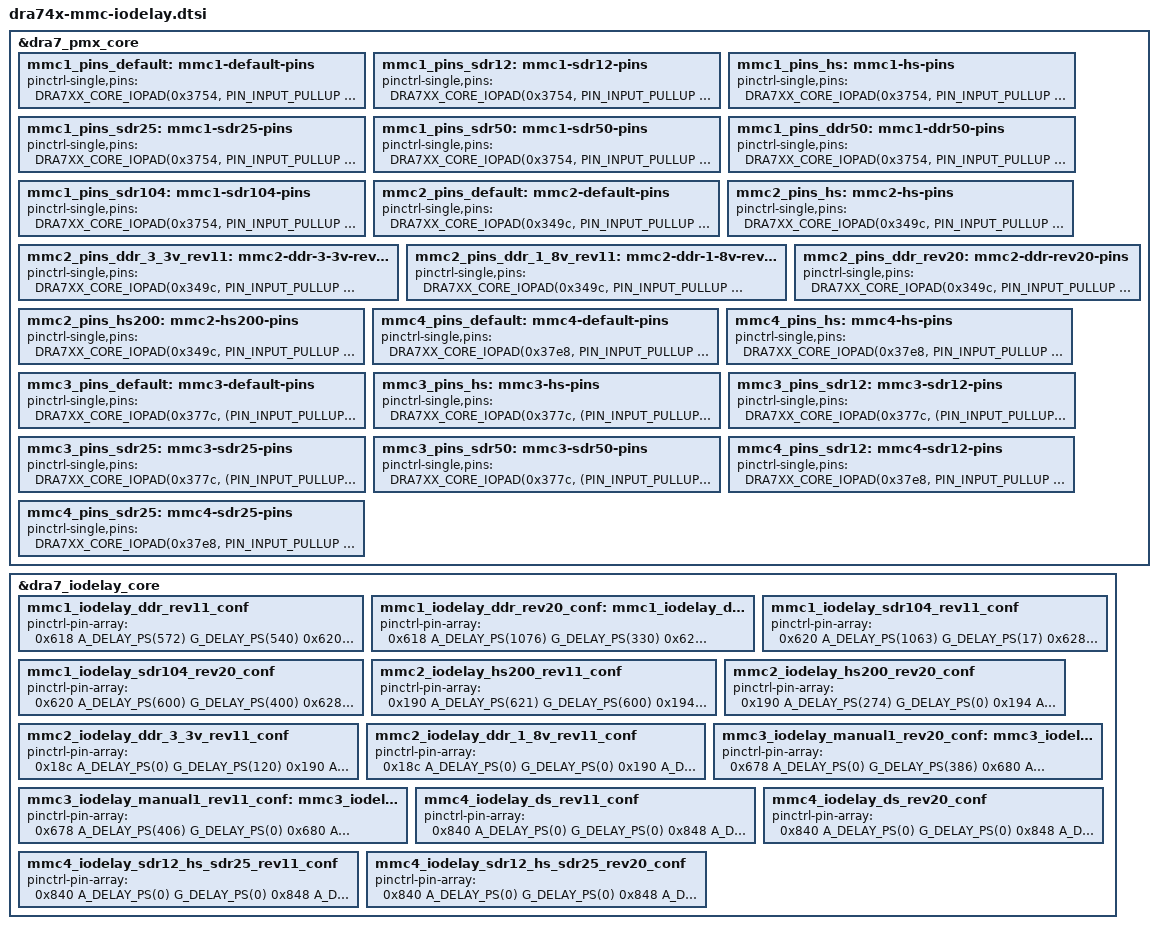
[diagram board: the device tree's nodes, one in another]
&dra7_pmx_core {
	mmc1_pins_default: mmc1-default-pins {
		pinctrl-single,pins = <
			DRA7XX_CORE_IOPAD(0x3754, PIN_INPUT_PULLUP | MUX_MODE0)  
			DRA7XX_CORE_IOPAD(0x3758, PIN_INPUT_PULLUP | MUX_MODE0)  
			DRA7XX_CORE_IOPAD(0x375c, PIN_INPUT_PULLUP | MUX_MODE0)  
			DRA7XX_CORE_IOPAD(0x3760, PIN_INPUT_PULLUP | MUX_MODE0)  
			DRA7XX_CORE_IOPAD(0x3764, PIN_INPUT_PULLUP | MUX_MODE0)  
			DRA7XX_CORE_IOPAD(0x3768, PIN_INPUT_PULLUP | MUX_MODE0)  
		>;
	};
	mmc1_pins_sdr12: mmc1-sdr12-pins {
		pinctrl-single,pins = <
			DRA7XX_CORE_IOPAD(0x3754, PIN_INPUT_PULLUP | MUX_MODE0)	 
			DRA7XX_CORE_IOPAD(0x3758, PIN_INPUT_PULLUP | MUX_MODE0)	 
			DRA7XX_CORE_IOPAD(0x375c, PIN_INPUT_PULLUP | MUX_MODE0)	 
			DRA7XX_CORE_IOPAD(0x3760, PIN_INPUT_PULLUP | MUX_MODE0)	 
			DRA7XX_CORE_IOPAD(0x3764, PIN_INPUT_PULLUP | MUX_MODE0)	 
			DRA7XX_CORE_IOPAD(0x3768, PIN_INPUT_PULLUP | MUX_MODE0)	 
		>;
	};
	mmc1_pins_hs: mmc1-hs-pins {
		pinctrl-single,pins = <
			DRA7XX_CORE_IOPAD(0x3754, PIN_INPUT_PULLUP | MUX_VIRTUAL_MODE11 | MUX_MODE0)  
			DRA7XX_CORE_IOPAD(0x3758, PIN_INPUT_PULLUP | MUX_VIRTUAL_MODE11 | MUX_MODE0)  
			DRA7XX_CORE_IOPAD(0x375c, PIN_INPUT_PULLUP | MUX_VIRTUAL_MODE11 | MUX_MODE0)  
			DRA7XX_CORE_IOPAD(0x3760, PIN_INPUT_PULLUP | MUX_VIRTUAL_MODE11 | MUX_MODE0)  
			DRA7XX_CORE_IOPAD(0x3764, PIN_INPUT_PULLUP | MUX_VIRTUAL_MODE11 | MUX_MODE0)  
			DRA7XX_CORE_IOPAD(0x3768, PIN_INPUT_PULLUP | MUX_VIRTUAL_MODE11 | MUX_MODE0)  
		>;
	};
	mmc1_pins_sdr25: mmc1-sdr25-pins {
		pinctrl-single,pins = <
			DRA7XX_CORE_IOPAD(0x3754, PIN_INPUT_PULLUP | MUX_VIRTUAL_MODE11 | MUX_MODE0)	 
			DRA7XX_CORE_IOPAD(0x3758, PIN_INPUT_PULLUP | MUX_VIRTUAL_MODE11 | MUX_MODE0)	 
			DRA7XX_CORE_IOPAD(0x375c, PIN_INPUT_PULLUP | MUX_VIRTUAL_MODE11 | MUX_MODE0)	 
			DRA7XX_CORE_IOPAD(0x3760, PIN_INPUT_PULLUP | MUX_VIRTUAL_MODE11 | MUX_MODE0)	 
			DRA7XX_CORE_IOPAD(0x3764, PIN_INPUT_PULLUP | MUX_VIRTUAL_MODE11 | MUX_MODE0)	 
			DRA7XX_CORE_IOPAD(0x3768, PIN_INPUT_PULLUP | MUX_VIRTUAL_MODE11 | MUX_MODE0)	 
		>;
	};
	mmc1_pins_sdr50: mmc1-sdr50-pins {
		pinctrl-single,pins = <
			DRA7XX_CORE_IOPAD(0x3754, PIN_INPUT_PULLUP | MUX_VIRTUAL_MODE10 | MUX_MODE0)	 
			DRA7XX_CORE_IOPAD(0x3758, PIN_INPUT_PULLUP | MUX_VIRTUAL_MODE10 | MUX_MODE0)	 
			DRA7XX_CORE_IOPAD(0x375c, PIN_INPUT_PULLUP | MUX_VIRTUAL_MODE10 | MUX_MODE0)	 
			DRA7XX_CORE_IOPAD(0x3760, PIN_INPUT_PULLUP | MUX_VIRTUAL_MODE10 | MUX_MODE0)	 
			DRA7XX_CORE_IOPAD(0x3764, PIN_INPUT_PULLUP | MUX_VIRTUAL_MODE10 | MUX_MODE0)	 
			DRA7XX_CORE_IOPAD(0x3768, PIN_INPUT_PULLUP | MUX_VIRTUAL_MODE10 | MUX_MODE0)	 
		>;
	};
	mmc1_pins_ddr50: mmc1-ddr50-pins {
		pinctrl-single,pins = <
			DRA7XX_CORE_IOPAD(0x3754, PIN_INPUT_PULLUP | MODE_SELECT | MUX_MODE0)	 
			DRA7XX_CORE_IOPAD(0x3758, PIN_INPUT_PULLUP | MODE_SELECT | MUX_MODE0)	 
			DRA7XX_CORE_IOPAD(0x375c, PIN_INPUT_PULLUP | MODE_SELECT | MUX_MODE0)	 
			DRA7XX_CORE_IOPAD(0x3760, PIN_INPUT_PULLUP | MODE_SELECT | MUX_MODE0)	 
			DRA7XX_CORE_IOPAD(0x3764, PIN_INPUT_PULLUP | MODE_SELECT | MUX_MODE0)	 
			DRA7XX_CORE_IOPAD(0x3768, PIN_INPUT_PULLUP | MODE_SELECT | MUX_MODE0)	 
		>;
	};
	mmc1_pins_sdr104: mmc1-sdr104-pins {
		pinctrl-single,pins = <
			DRA7XX_CORE_IOPAD(0x3754, PIN_INPUT_PULLUP | MODE_SELECT | MUX_MODE0)	 
			DRA7XX_CORE_IOPAD(0x3758, PIN_INPUT_PULLUP | MODE_SELECT | MUX_MODE0)	 
			DRA7XX_CORE_IOPAD(0x375c, PIN_INPUT_PULLUP | MODE_SELECT | MUX_MODE0)	 
			DRA7XX_CORE_IOPAD(0x3760, PIN_INPUT_PULLUP | MODE_SELECT | MUX_MODE0)	 
			DRA7XX_CORE_IOPAD(0x3764, PIN_INPUT_PULLUP | MODE_SELECT | MUX_MODE0)	 
			DRA7XX_CORE_IOPAD(0x3768, PIN_INPUT_PULLUP | MODE_SELECT | MUX_MODE0)	 
		>;
	};
	mmc2_pins_default: mmc2-default-pins {
		pinctrl-single,pins = <
			DRA7XX_CORE_IOPAD(0x349c, PIN_INPUT_PULLUP | MUX_MODE1)  
			DRA7XX_CORE_IOPAD(0x34b0, PIN_INPUT_PULLUP | MUX_MODE1)  
			DRA7XX_CORE_IOPAD(0x34a0, PIN_INPUT_PULLUP | MUX_MODE1)  
			DRA7XX_CORE_IOPAD(0x34a4, PIN_INPUT_PULLUP | MUX_MODE1)  
			DRA7XX_CORE_IOPAD(0x34a8, PIN_INPUT_PULLUP | MUX_MODE1)  
			DRA7XX_CORE_IOPAD(0x34ac, PIN_INPUT_PULLUP | MUX_MODE1)  
			DRA7XX_CORE_IOPAD(0x348c, PIN_INPUT_PULLUP | MUX_MODE1)  
			DRA7XX_CORE_IOPAD(0x3490, PIN_INPUT_PULLUP | MUX_MODE1)  
			DRA7XX_CORE_IOPAD(0x3494, PIN_INPUT_PULLUP | MUX_MODE1)  
			DRA7XX_CORE_IOPAD(0x3498, PIN_INPUT_PULLUP | MUX_MODE1)  
		>;
	};
	mmc2_pins_hs: mmc2-hs-pins {
		pinctrl-single,pins = <
			DRA7XX_CORE_IOPAD(0x349c, PIN_INPUT_PULLUP | MUX_MODE1)  
			DRA7XX_CORE_IOPAD(0x34b0, PIN_INPUT_PULLUP | MUX_MODE1)  
			DRA7XX_CORE_IOPAD(0x34a0, PIN_INPUT_PULLUP | MUX_MODE1)  
			DRA7XX_CORE_IOPAD(0x34a4, PIN_INPUT_PULLUP | MUX_MODE1)  
			DRA7XX_CORE_IOPAD(0x34a8, PIN_INPUT_PULLUP | MUX_MODE1)  
			DRA7XX_CORE_IOPAD(0x34ac, PIN_INPUT_PULLUP | MUX_MODE1)  
			DRA7XX_CORE_IOPAD(0x348c, PIN_INPUT_PULLUP | MUX_MODE1)  
			DRA7XX_CORE_IOPAD(0x3490, PIN_INPUT_PULLUP | MUX_MODE1)  
			DRA7XX_CORE_IOPAD(0x3494, PIN_INPUT_PULLUP | MUX_MODE1)  
			DRA7XX_CORE_IOPAD(0x3498, PIN_INPUT_PULLUP | MUX_MODE1)  
		>;
	};
	mmc2_pins_ddr_3_3v_rev11: mmc2-ddr-3-3v-rev11-pins {
		pinctrl-single,pins = <
			DRA7XX_CORE_IOPAD(0x349c, PIN_INPUT_PULLUP | MODE_SELECT | MUX_MODE1)  
			DRA7XX_CORE_IOPAD(0x34b0, PIN_INPUT_PULLUP | MODE_SELECT | MUX_MODE1)  
			DRA7XX_CORE_IOPAD(0x34a0, PIN_INPUT_PULLUP | MODE_SELECT | MUX_MODE1)  
			DRA7XX_CORE_IOPAD(0x34a4, PIN_INPUT_PULLUP | MODE_SELECT | MUX_MODE1)  
			DRA7XX_CORE_IOPAD(0x34a8, PIN_INPUT_PULLUP | MODE_SELECT | MUX_MODE1)  
			DRA7XX_CORE_IOPAD(0x34ac, PIN_INPUT_PULLUP | MODE_SELECT | MUX_MODE1)  
			DRA7XX_CORE_IOPAD(0x348c, PIN_INPUT_PULLUP | MODE_SELECT | MUX_MODE1)  
			DRA7XX_CORE_IOPAD(0x3490, PIN_INPUT_PULLUP | MODE_SELECT | MUX_MODE1)  
			DRA7XX_CORE_IOPAD(0x3494, PIN_INPUT_PULLUP | MODE_SELECT | MUX_MODE1)  
			DRA7XX_CORE_IOPAD(0x3498, PIN_INPUT_PULLUP | MODE_SELECT | MUX_MODE1)  
		>;
	};
	mmc2_pins_ddr_1_8v_rev11: mmc2-ddr-1-8v-rev11-pins {
		pinctrl-single,pins = <
			DRA7XX_CORE_IOPAD(0x349c, PIN_INPUT_PULLUP | MODE_SELECT | MUX_MODE1)  
			DRA7XX_CORE_IOPAD(0x34b0, PIN_INPUT_PULLUP | MODE_SELECT | MUX_MODE1)  
			DRA7XX_CORE_IOPAD(0x34a0, PIN_INPUT_PULLUP | MODE_SELECT | MUX_MODE1)  
			DRA7XX_CORE_IOPAD(0x34a4, PIN_INPUT_PULLUP | MODE_SELECT | MUX_MODE1)  
			DRA7XX_CORE_IOPAD(0x34a8, PIN_INPUT_PULLUP | MODE_SELECT | MUX_MODE1)  
			DRA7XX_CORE_IOPAD(0x34ac, PIN_INPUT_PULLUP | MODE_SELECT | MUX_MODE1)  
			DRA7XX_CORE_IOPAD(0x348c, PIN_INPUT_PULLUP | MODE_SELECT | MUX_MODE1)  
			DRA7XX_CORE_IOPAD(0x3490, PIN_INPUT_PULLUP | MODE_SELECT | MUX_MODE1)  
			DRA7XX_CORE_IOPAD(0x3494, PIN_INPUT_PULLUP | MODE_SELECT | MUX_MODE1)  
			DRA7XX_CORE_IOPAD(0x3498, PIN_INPUT_PULLUP | MODE_SELECT | MUX_MODE1)  
		>;
	};
	mmc2_pins_ddr_rev20: mmc2-ddr-rev20-pins {
		pinctrl-single,pins = <
			DRA7XX_CORE_IOPAD(0x349c, PIN_INPUT_PULLUP | MUX_MODE1)  
			DRA7XX_CORE_IOPAD(0x34b0, PIN_INPUT_PULLUP | MUX_MODE1)  
			DRA7XX_CORE_IOPAD(0x34a0, PIN_INPUT_PULLUP | MUX_MODE1)  
			DRA7XX_CORE_IOPAD(0x34a4, PIN_INPUT_PULLUP | MUX_MODE1)  
			DRA7XX_CORE_IOPAD(0x34a8, PIN_INPUT_PULLUP | MUX_MODE1)  
			DRA7XX_CORE_IOPAD(0x34ac, PIN_INPUT_PULLUP | MUX_MODE1)  
			DRA7XX_CORE_IOPAD(0x348c, PIN_INPUT_PULLUP | MUX_MODE1)  
			DRA7XX_CORE_IOPAD(0x3490, PIN_INPUT_PULLUP | MUX_MODE1)  
			DRA7XX_CORE_IOPAD(0x3494, PIN_INPUT_PULLUP | MUX_MODE1)  
			DRA7XX_CORE_IOPAD(0x3498, PIN_INPUT_PULLUP | MUX_MODE1)  
		>;
	};
	mmc2_pins_hs200: mmc2-hs200-pins {
		pinctrl-single,pins = <
			DRA7XX_CORE_IOPAD(0x349c, PIN_INPUT_PULLUP | MODE_SELECT | MUX_MODE1)  
			DRA7XX_CORE_IOPAD(0x34b0, PIN_INPUT_PULLUP | MODE_SELECT | MUX_MODE1)  
			DRA7XX_CORE_IOPAD(0x34a0, PIN_INPUT_PULLUP | MODE_SELECT | MUX_MODE1)  
			DRA7XX_CORE_IOPAD(0x34a4, PIN_INPUT_PULLUP | MODE_SELECT | MUX_MODE1)  
			DRA7XX_CORE_IOPAD(0x34a8, PIN_INPUT_PULLUP | MODE_SELECT | MUX_MODE1)  
			DRA7XX_CORE_IOPAD(0x34ac, PIN_INPUT_PULLUP | MODE_SELECT | MUX_MODE1)  
			DRA7XX_CORE_IOPAD(0x348c, PIN_INPUT_PULLUP | MODE_SELECT | MUX_MODE1)  
			DRA7XX_CORE_IOPAD(0x3490, PIN_INPUT_PULLUP | MODE_SELECT | MUX_MODE1)  
			DRA7XX_CORE_IOPAD(0x3494, PIN_INPUT_PULLUP | MODE_SELECT | MUX_MODE1)  
			DRA7XX_CORE_IOPAD(0x3498, PIN_INPUT_PULLUP | MODE_SELECT | MUX_MODE1)  
		>;
	};
	mmc4_pins_default: mmc4-default-pins {
		pinctrl-single,pins = <
			DRA7XX_CORE_IOPAD(0x37e8, PIN_INPUT_PULLUP | MODE_SELECT | MUX_MODE3)  
			DRA7XX_CORE_IOPAD(0x37ec, PIN_INPUT_PULLUP | MODE_SELECT | MUX_MODE3)  
			DRA7XX_CORE_IOPAD(0x37f0, PIN_INPUT_PULLUP | MODE_SELECT | MUX_MODE3)  
			DRA7XX_CORE_IOPAD(0x37f4, PIN_INPUT_PULLUP | MODE_SELECT | MUX_MODE3)  
			DRA7XX_CORE_IOPAD(0x37f8, PIN_INPUT_PULLUP | MODE_SELECT | MUX_MODE3)  
			DRA7XX_CORE_IOPAD(0x37fc, PIN_INPUT_PULLUP | MODE_SELECT | MUX_MODE3)  
		>;
	};
	mmc4_pins_hs: mmc4-hs-pins {
		pinctrl-single,pins = <
			DRA7XX_CORE_IOPAD(0x37e8, PIN_INPUT_PULLUP | MODE_SELECT | MUX_MODE3)  
			DRA7XX_CORE_IOPAD(0x37ec, PIN_INPUT_PULLUP | MODE_SELECT | MUX_MODE3)  
			DRA7XX_CORE_IOPAD(0x37f0, PIN_INPUT_PULLUP | MODE_SELECT | MUX_MODE3)  
			DRA7XX_CORE_IOPAD(0x37f4, PIN_INPUT_PULLUP | MODE_SELECT | MUX_MODE3)  
			DRA7XX_CORE_IOPAD(0x37f8, PIN_INPUT_PULLUP | MODE_SELECT | MUX_MODE3)  
			DRA7XX_CORE_IOPAD(0x37fc, PIN_INPUT_PULLUP | MODE_SELECT | MUX_MODE3)  
		>;
	};
	mmc3_pins_default: mmc3-default-pins {
		pinctrl-single,pins = <
			DRA7XX_CORE_IOPAD(0x377c, (PIN_INPUT_PULLUP | MODE_SELECT | MUX_MODE0))  
			DRA7XX_CORE_IOPAD(0x3780, (PIN_INPUT_PULLUP | MODE_SELECT | MUX_MODE0))  
			DRA7XX_CORE_IOPAD(0x3784, (PIN_INPUT_PULLUP | MODE_SELECT | MUX_MODE0))  
			DRA7XX_CORE_IOPAD(0x3788, (PIN_INPUT_PULLUP | MODE_SELECT | MUX_MODE0))  
			DRA7XX_CORE_IOPAD(0x378c, (PIN_INPUT_PULLUP | MODE_SELECT | MUX_MODE0))  
			DRA7XX_CORE_IOPAD(0x3790, (PIN_INPUT_PULLUP | MODE_SELECT | MUX_MODE0))  
		>;
	};
	mmc3_pins_hs: mmc3-hs-pins {
		pinctrl-single,pins = <
			DRA7XX_CORE_IOPAD(0x377c, (PIN_INPUT_PULLUP | MODE_SELECT | MUX_MODE0))  
			DRA7XX_CORE_IOPAD(0x3780, (PIN_INPUT_PULLUP | MODE_SELECT | MUX_MODE0))  
			DRA7XX_CORE_IOPAD(0x3784, (PIN_INPUT_PULLUP | MODE_SELECT | MUX_MODE0))  
			DRA7XX_CORE_IOPAD(0x3788, (PIN_INPUT_PULLUP | MODE_SELECT | MUX_MODE0))  
			DRA7XX_CORE_IOPAD(0x378c, (PIN_INPUT_PULLUP | MODE_SELECT | MUX_MODE0))  
			DRA7XX_CORE_IOPAD(0x3790, (PIN_INPUT_PULLUP | MODE_SELECT | MUX_MODE0))  
		>;
	};
	mmc3_pins_sdr12: mmc3-sdr12-pins {
		pinctrl-single,pins = <
			DRA7XX_CORE_IOPAD(0x377c, (PIN_INPUT_PULLUP | MODE_SELECT | MUX_MODE0))  
			DRA7XX_CORE_IOPAD(0x3780, (PIN_INPUT_PULLUP | MODE_SELECT | MUX_MODE0))  
			DRA7XX_CORE_IOPAD(0x3784, (PIN_INPUT_PULLUP | MODE_SELECT | MUX_MODE0))  
			DRA7XX_CORE_IOPAD(0x3788, (PIN_INPUT_PULLUP | MODE_SELECT | MUX_MODE0))  
			DRA7XX_CORE_IOPAD(0x378c, (PIN_INPUT_PULLUP | MODE_SELECT | MUX_MODE0))  
			DRA7XX_CORE_IOPAD(0x3790, (PIN_INPUT_PULLUP | MODE_SELECT | MUX_MODE0))  
		>;
	};
	mmc3_pins_sdr25: mmc3-sdr25-pins {
		pinctrl-single,pins = <
			DRA7XX_CORE_IOPAD(0x377c, (PIN_INPUT_PULLUP | MODE_SELECT | MUX_MODE0))  
			DRA7XX_CORE_IOPAD(0x3780, (PIN_INPUT_PULLUP | MODE_SELECT | MUX_MODE0))  
			DRA7XX_CORE_IOPAD(0x3784, (PIN_INPUT_PULLUP | MODE_SELECT | MUX_MODE0))  
			DRA7XX_CORE_IOPAD(0x3788, (PIN_INPUT_PULLUP | MODE_SELECT | MUX_MODE0))  
			DRA7XX_CORE_IOPAD(0x378c, (PIN_INPUT_PULLUP | MODE_SELECT | MUX_MODE0))  
			DRA7XX_CORE_IOPAD(0x3790, (PIN_INPUT_PULLUP | MODE_SELECT | MUX_MODE0))  
		>;
	};
	mmc3_pins_sdr50: mmc3-sdr50-pins {
		pinctrl-single,pins = <
			DRA7XX_CORE_IOPAD(0x377c, (PIN_INPUT_PULLUP | MODE_SELECT | MUX_MODE0))  
			DRA7XX_CORE_IOPAD(0x3780, (PIN_INPUT_PULLUP | MODE_SELECT | MUX_MODE0))  
			DRA7XX_CORE_IOPAD(0x3784, (PIN_INPUT_PULLUP | MODE_SELECT | MUX_MODE0))  
			DRA7XX_CORE_IOPAD(0x3788, (PIN_INPUT_PULLUP | MODE_SELECT | MUX_MODE0))  
			DRA7XX_CORE_IOPAD(0x378c, (PIN_INPUT_PULLUP | MODE_SELECT | MUX_MODE0))  
			DRA7XX_CORE_IOPAD(0x3790, (PIN_INPUT_PULLUP | MODE_SELECT | MUX_MODE0))  
		>;
	};
	mmc4_pins_sdr12: mmc4-sdr12-pins {
		pinctrl-single,pins = <
			DRA7XX_CORE_IOPAD(0x37e8, PIN_INPUT_PULLUP | MODE_SELECT | MUX_MODE3)  
			DRA7XX_CORE_IOPAD(0x37ec, PIN_INPUT_PULLUP | MODE_SELECT | MUX_MODE3)  
			DRA7XX_CORE_IOPAD(0x37f0, PIN_INPUT_PULLUP | MODE_SELECT | MUX_MODE3)  
			DRA7XX_CORE_IOPAD(0x37f4, PIN_INPUT_PULLUP | MODE_SELECT | MUX_MODE3)  
			DRA7XX_CORE_IOPAD(0x37f8, PIN_INPUT_PULLUP | MODE_SELECT | MUX_MODE3)  
			DRA7XX_CORE_IOPAD(0x37fc, PIN_INPUT_PULLUP | MODE_SELECT | MUX_MODE3)  
		>;
	};
	mmc4_pins_sdr25: mmc4-sdr25-pins {
		pinctrl-single,pins = <
			DRA7XX_CORE_IOPAD(0x37e8, PIN_INPUT_PULLUP | MODE_SELECT | MUX_MODE3)  
			DRA7XX_CORE_IOPAD(0x37ec, PIN_INPUT_PULLUP | MODE_SELECT | MUX_MODE3)  
			DRA7XX_CORE_IOPAD(0x37f0, PIN_INPUT_PULLUP | MODE_SELECT | MUX_MODE3)  
			DRA7XX_CORE_IOPAD(0x37f4, PIN_INPUT_PULLUP | MODE_SELECT | MUX_MODE3)  
			DRA7XX_CORE_IOPAD(0x37f8, PIN_INPUT_PULLUP | MODE_SELECT | MUX_MODE3)  
			DRA7XX_CORE_IOPAD(0x37fc, PIN_INPUT_PULLUP | MODE_SELECT | MUX_MODE3)  
		>;
	};
};
&dra7_iodelay_core {
	mmc1_iodelay_ddr_rev11_conf: mmc1_iodelay_ddr_rev11_conf {
		pinctrl-pin-array = <
			0x618 A_DELAY_PS(572) G_DELAY_PS(540)	 
			0x620 A_DELAY_PS(1525) G_DELAY_PS(0)	 
			0x624 A_DELAY_PS(0) G_DELAY_PS(600)	 
			0x628 A_DELAY_PS(0) G_DELAY_PS(0)	 
			0x62c A_DELAY_PS(55) G_DELAY_PS(0)	 
			0x630 A_DELAY_PS(403) G_DELAY_PS(120)	 
			0x634 A_DELAY_PS(0) G_DELAY_PS(0)	 
			0x638 A_DELAY_PS(0) G_DELAY_PS(0)	 
			0x63c A_DELAY_PS(23) G_DELAY_PS(60)	 
			0x640 A_DELAY_PS(0) G_DELAY_PS(0)	 
			0x644 A_DELAY_PS(0) G_DELAY_PS(0)	 
			0x648 A_DELAY_PS(25) G_DELAY_PS(60)	 
			0x64c A_DELAY_PS(0) G_DELAY_PS(0)	 
			0x650 A_DELAY_PS(0) G_DELAY_PS(0)	 
			0x654 A_DELAY_PS(0) G_DELAY_PS(0)	 
			0x658 A_DELAY_PS(0) G_DELAY_PS(0)	 
			0x65c A_DELAY_PS(0) G_DELAY_PS(0)	 
		>;
	};
	mmc1_iodelay_ddr_rev20_conf: mmc1_iodelay_ddr50_rev20_conf {
		pinctrl-pin-array = <
			0x618 A_DELAY_PS(1076) G_DELAY_PS(330)	 
			0x620 A_DELAY_PS(1271) G_DELAY_PS(0)	 
			0x624 A_DELAY_PS(722) G_DELAY_PS(0)	 
			0x628 A_DELAY_PS(0) G_DELAY_PS(0)	 
			0x62C A_DELAY_PS(0) G_DELAY_PS(0)	 
			0x630 A_DELAY_PS(751) G_DELAY_PS(0)	 
			0x634 A_DELAY_PS(0) G_DELAY_PS(0)	 
			0x638 A_DELAY_PS(20) G_DELAY_PS(0)	 
			0x63C A_DELAY_PS(256) G_DELAY_PS(0)	 
			0x640 A_DELAY_PS(0) G_DELAY_PS(0)	 
			0x644 A_DELAY_PS(0) G_DELAY_PS(0)	 
			0x648 A_DELAY_PS(263) G_DELAY_PS(0)	 
			0x64C A_DELAY_PS(0) G_DELAY_PS(0)	 
			0x650 A_DELAY_PS(0) G_DELAY_PS(0)	 
			0x654 A_DELAY_PS(0) G_DELAY_PS(0)	 
			0x658 A_DELAY_PS(0) G_DELAY_PS(0)	 
			0x65C A_DELAY_PS(0) G_DELAY_PS(0)	 
		>;
	};
	mmc1_iodelay_sdr104_rev11_conf: mmc1_iodelay_sdr104_rev11_conf {
		pinctrl-pin-array = <
			0x620 A_DELAY_PS(1063) G_DELAY_PS(17)	 
			0x628 A_DELAY_PS(0) G_DELAY_PS(0)	 
			0x62c A_DELAY_PS(23) G_DELAY_PS(0)	 
			0x634 A_DELAY_PS(0) G_DELAY_PS(0)	 
			0x638 A_DELAY_PS(0) G_DELAY_PS(0)	 
			0x640 A_DELAY_PS(0) G_DELAY_PS(0)	 
			0x644 A_DELAY_PS(2) G_DELAY_PS(0)	 
			0x64c A_DELAY_PS(0) G_DELAY_PS(0)	 
			0x650 A_DELAY_PS(0) G_DELAY_PS(0)	 
			0x658 A_DELAY_PS(0) G_DELAY_PS(0)	 
			0x65c A_DELAY_PS(0) G_DELAY_PS(0)	 
		>;
	};
	mmc1_iodelay_sdr104_rev20_conf: mmc1_iodelay_sdr104_rev20_conf {
		pinctrl-pin-array = <
			0x620 A_DELAY_PS(600) G_DELAY_PS(400)	 
			0x628 A_DELAY_PS(0) G_DELAY_PS(0)	 
			0x62c A_DELAY_PS(0) G_DELAY_PS(0)	 
			0x634 A_DELAY_PS(0) G_DELAY_PS(0)	 
			0x638 A_DELAY_PS(30) G_DELAY_PS(0)	 
			0x640 A_DELAY_PS(0) G_DELAY_PS(0)	 
			0x644 A_DELAY_PS(0) G_DELAY_PS(0)	 
			0x64c A_DELAY_PS(0) G_DELAY_PS(0)	 
			0x650 A_DELAY_PS(0) G_DELAY_PS(0)	 
			0x658 A_DELAY_PS(0) G_DELAY_PS(0)	 
			0x65c A_DELAY_PS(0) G_DELAY_PS(0)	 
		>;
	};
	mmc2_iodelay_hs200_rev11_conf: mmc2_iodelay_hs200_rev11_conf {
		pinctrl-pin-array = <
			0x190 A_DELAY_PS(621) G_DELAY_PS(600)	 
			0x194 A_DELAY_PS(300) G_DELAY_PS(0)	 
			0x1a8 A_DELAY_PS(739) G_DELAY_PS(600)	 
			0x1ac A_DELAY_PS(240) G_DELAY_PS(0)	 
			0x1b4 A_DELAY_PS(812) G_DELAY_PS(600)	 
			0x1b8 A_DELAY_PS(240) G_DELAY_PS(0)	 
			0x1c0 A_DELAY_PS(954) G_DELAY_PS(600)	 
			0x1c4 A_DELAY_PS(60)  G_DELAY_PS(0)	 
			0x1d0 A_DELAY_PS(1340) G_DELAY_PS(420)	 
			0x1d8 A_DELAY_PS(935) G_DELAY_PS(600)	 
			0x1dc A_DELAY_PS(0) G_DELAY_PS(0)	 
			0x1e4 A_DELAY_PS(525) G_DELAY_PS(600)	 
			0x1e8 A_DELAY_PS(120) G_DELAY_PS(0)	 
			0x1f0 A_DELAY_PS(767) G_DELAY_PS(600)	 
			0x1f4 A_DELAY_PS(225) G_DELAY_PS(0)	 
			0x1fc A_DELAY_PS(565) G_DELAY_PS(600)	 
			0x200 A_DELAY_PS(60) G_DELAY_PS(0)	 
			0x364 A_DELAY_PS(969) G_DELAY_PS(600)	 
			0x368 A_DELAY_PS(180) G_DELAY_PS(0)	 
	      >;
	};
	mmc2_iodelay_hs200_rev20_conf: mmc2_iodelay_hs200_rev20_conf {
		pinctrl-pin-array = <
			0x190 A_DELAY_PS(274) G_DELAY_PS(0)        
			0x194 A_DELAY_PS(162) G_DELAY_PS(0)        
			0x1a8 A_DELAY_PS(401) G_DELAY_PS(0)        
			0x1ac A_DELAY_PS(73) G_DELAY_PS(0)         
			0x1b4 A_DELAY_PS(465) G_DELAY_PS(0)        
			0x1b8 A_DELAY_PS(115) G_DELAY_PS(0)        
			0x1c0 A_DELAY_PS(633) G_DELAY_PS(0)        
			0x1c4 A_DELAY_PS(47) G_DELAY_PS(0)         
			0x1d0 A_DELAY_PS(935) G_DELAY_PS(280)      
			0x1d8 A_DELAY_PS(621) G_DELAY_PS(0)        
			0x1dc A_DELAY_PS(0) G_DELAY_PS(0)          
			0x1e4 A_DELAY_PS(183) G_DELAY_PS(0)        
			0x1e8 A_DELAY_PS(0) G_DELAY_PS(0)          
			0x1f0 A_DELAY_PS(467) G_DELAY_PS(0)        
			0x1f4 A_DELAY_PS(0) G_DELAY_PS(0)          
			0x1fc A_DELAY_PS(262) G_DELAY_PS(0)        
			0x200 A_DELAY_PS(46) G_DELAY_PS(0)         
			0x364 A_DELAY_PS(684) G_DELAY_PS(0)        
			0x368 A_DELAY_PS(76) G_DELAY_PS(0)         
	      >;
	};
	mmc2_iodelay_ddr_3_3v_rev11_conf: mmc2_iodelay_ddr_3_3v_rev11_conf {
		pinctrl-pin-array = <
			0x18c A_DELAY_PS(0) G_DELAY_PS(120)	 
			0x190 A_DELAY_PS(0) G_DELAY_PS(0)	 
			0x194 A_DELAY_PS(174) G_DELAY_PS(0)	 
			0x1a4 A_DELAY_PS(265) G_DELAY_PS(360)	 
			0x1a8 A_DELAY_PS(0) G_DELAY_PS(0)	 
			0x1ac A_DELAY_PS(168) G_DELAY_PS(0)	 
			0x1b0 A_DELAY_PS(0) G_DELAY_PS(120)	 
			0x1b4 A_DELAY_PS(0) G_DELAY_PS(0)	 
			0x1b8 A_DELAY_PS(136) G_DELAY_PS(0)	 
			0x1bc A_DELAY_PS(0) G_DELAY_PS(120)	 
			0x1c0 A_DELAY_PS(0) G_DELAY_PS(0)	 
			0x1c4 A_DELAY_PS(0) G_DELAY_PS(0)	 
			0x1c8 A_DELAY_PS(287) G_DELAY_PS(420)	 
			0x1d0 A_DELAY_PS(879) G_DELAY_PS(0)	 
			0x1d4 A_DELAY_PS(144) G_DELAY_PS(240)	 
			0x1d8 A_DELAY_PS(0) G_DELAY_PS(0)	 
			0x1dc A_DELAY_PS(0) G_DELAY_PS(0)	 
			0x1e0 A_DELAY_PS(0) G_DELAY_PS(0)	 
			0x1e4 A_DELAY_PS(0) G_DELAY_PS(0)	 
			0x1e8 A_DELAY_PS(34) G_DELAY_PS(0)	 
			0x1ec A_DELAY_PS(0) G_DELAY_PS(120)	 
			0x1f0 A_DELAY_PS(0) G_DELAY_PS(0)	 
			0x1f4 A_DELAY_PS(120) G_DELAY_PS(0)	 
			0x1f8 A_DELAY_PS(120) G_DELAY_PS(180)	 
			0x1fc A_DELAY_PS(0) G_DELAY_PS(0)	 
			0x200 A_DELAY_PS(0) G_DELAY_PS(0)	 
			0x360 A_DELAY_PS(0) G_DELAY_PS(0)	 
			0x364 A_DELAY_PS(0) G_DELAY_PS(0)	 
			0x368 A_DELAY_PS(11) G_DELAY_PS(0)	 
		>;
	};
	mmc2_iodelay_ddr_1_8v_rev11_conf: mmc2_iodelay_ddr_1_8v_rev11_conf {
		pinctrl-pin-array = <
			0x18c A_DELAY_PS(0) G_DELAY_PS(0)	 
			0x190 A_DELAY_PS(0) G_DELAY_PS(0)	 
			0x194 A_DELAY_PS(174) G_DELAY_PS(0)	 
			0x1a4 A_DELAY_PS(274) G_DELAY_PS(240)	 
			0x1a8 A_DELAY_PS(0) G_DELAY_PS(0)	 
			0x1ac A_DELAY_PS(168) G_DELAY_PS(0)	 
			0x1b0 A_DELAY_PS(0) G_DELAY_PS(60)	 
			0x1b4 A_DELAY_PS(0) G_DELAY_PS(0)	 
			0x1b8 A_DELAY_PS(136) G_DELAY_PS(0)	 
			0x1bc A_DELAY_PS(0) G_DELAY_PS(60)	 
			0x1c0 A_DELAY_PS(0) G_DELAY_PS(0)	 
			0x1c4 A_DELAY_PS(0) G_DELAY_PS(0)	 
			0x1c8 A_DELAY_PS(514) G_DELAY_PS(360)	 
			0x1d0 A_DELAY_PS(879) G_DELAY_PS(0)	 
			0x1d4 A_DELAY_PS(187) G_DELAY_PS(120)	 
			0x1d8 A_DELAY_PS(0) G_DELAY_PS(0)	 
			0x1dc A_DELAY_PS(0) G_DELAY_PS(0)	 
			0x1e0 A_DELAY_PS(0) G_DELAY_PS(0)	 
			0x1e4 A_DELAY_PS(0) G_DELAY_PS(0)	 
			0x1e8 A_DELAY_PS(34) G_DELAY_PS(0)	 
			0x1ec A_DELAY_PS(0) G_DELAY_PS(60)	 
			0x1f0 A_DELAY_PS(0) G_DELAY_PS(0)	 
			0x1f4 A_DELAY_PS(120) G_DELAY_PS(0)	 
			0x1f8 A_DELAY_PS(121) G_DELAY_PS(60)	 
			0x1fc A_DELAY_PS(0) G_DELAY_PS(0)	 
			0x200 A_DELAY_PS(0) G_DELAY_PS(0)	 
			0x360 A_DELAY_PS(0) G_DELAY_PS(0)	 
			0x364 A_DELAY_PS(0) G_DELAY_PS(0)	 
			0x368 A_DELAY_PS(11) G_DELAY_PS(0)	 
		>;
	};
	mmc3_iodelay_manual1_rev20_conf: mmc3_iodelay_manual1_conf {
		pinctrl-pin-array = <
			0x678 A_DELAY_PS(0) G_DELAY_PS(386)	 
			0x680 A_DELAY_PS(605) G_DELAY_PS(0)	 
			0x684 A_DELAY_PS(0) G_DELAY_PS(0)	 
			0x688 A_DELAY_PS(0) G_DELAY_PS(0)	 
			0x68c A_DELAY_PS(0) G_DELAY_PS(0)	 
			0x690 A_DELAY_PS(171) G_DELAY_PS(0)	 
			0x694 A_DELAY_PS(0) G_DELAY_PS(0)	 
			0x698 A_DELAY_PS(0) G_DELAY_PS(0)	 
			0x69c A_DELAY_PS(221) G_DELAY_PS(0)	 
			0x6a0 A_DELAY_PS(0) G_DELAY_PS(0)	 
			0x6a4 A_DELAY_PS(0) G_DELAY_PS(0)	 
			0x6a8 A_DELAY_PS(0) G_DELAY_PS(0)	 
			0x6ac A_DELAY_PS(0) G_DELAY_PS(0)	 
			0x6b0 A_DELAY_PS(0) G_DELAY_PS(0)	 
			0x6b4 A_DELAY_PS(474) G_DELAY_PS(0)	 
			0x6b8 A_DELAY_PS(0) G_DELAY_PS(0)	 
			0x6bc A_DELAY_PS(0) G_DELAY_PS(0)	 
		>;
	};
	mmc3_iodelay_manual1_rev11_conf: mmc3_iodelay_manual1_conf {
		pinctrl-pin-array = <
			0x678 A_DELAY_PS(406) G_DELAY_PS(0)	 
			0x680 A_DELAY_PS(659) G_DELAY_PS(0)	 
			0x684 A_DELAY_PS(0) G_DELAY_PS(0)	 
			0x688 A_DELAY_PS(0) G_DELAY_PS(0)	 
			0x68c A_DELAY_PS(0) G_DELAY_PS(0)	 
			0x690 A_DELAY_PS(130) G_DELAY_PS(0)	 
			0x694 A_DELAY_PS(0) G_DELAY_PS(0)	 
			0x698 A_DELAY_PS(0) G_DELAY_PS(0)	 
			0x69c A_DELAY_PS(169) G_DELAY_PS(0)	 
			0x6a0 A_DELAY_PS(0) G_DELAY_PS(0)	 
			0x6a4 A_DELAY_PS(0) G_DELAY_PS(0)	 
			0x6a8 A_DELAY_PS(0) G_DELAY_PS(0)	 
			0x6ac A_DELAY_PS(0) G_DELAY_PS(0)	 
			0x6b0 A_DELAY_PS(0) G_DELAY_PS(0)	 
			0x6b4 A_DELAY_PS(457) G_DELAY_PS(0)	 
			0x6b8 A_DELAY_PS(0) G_DELAY_PS(0)	 
			0x6bc A_DELAY_PS(0) G_DELAY_PS(0)	 
		>;
	};
	mmc4_iodelay_ds_rev11_conf: mmc4_iodelay_ds_rev11_conf {
		pinctrl-pin-array = <
			0x840 A_DELAY_PS(0) G_DELAY_PS(0)	 
			0x848 A_DELAY_PS(0) G_DELAY_PS(0)	 
			0x84c A_DELAY_PS(96) G_DELAY_PS(0)	 
			0x850 A_DELAY_PS(0) G_DELAY_PS(0)	 
			0x854 A_DELAY_PS(0) G_DELAY_PS(0)	 
			0x870 A_DELAY_PS(582) G_DELAY_PS(0)	 
			0x874 A_DELAY_PS(0) G_DELAY_PS(0)	 
			0x878 A_DELAY_PS(0) G_DELAY_PS(0)	 
			0x87c A_DELAY_PS(391) G_DELAY_PS(0)	 
			0x880 A_DELAY_PS(0) G_DELAY_PS(0)	 
			0x884 A_DELAY_PS(0) G_DELAY_PS(0)	 
			0x888 A_DELAY_PS(561) G_DELAY_PS(0)	 
			0x88c A_DELAY_PS(0) G_DELAY_PS(0)	 
			0x890 A_DELAY_PS(0) G_DELAY_PS(0)	 
			0x894 A_DELAY_PS(588) G_DELAY_PS(0)	 
			0x898 A_DELAY_PS(0) G_DELAY_PS(0)	 
			0x89c A_DELAY_PS(0) G_DELAY_PS(0)	 
		>;
	};
	mmc4_iodelay_ds_rev20_conf: mmc4_iodelay_ds_rev20_conf {
		pinctrl-pin-array = <
			0x840 A_DELAY_PS(0) G_DELAY_PS(0)	 
			0x848 A_DELAY_PS(0) G_DELAY_PS(0)	 
			0x84c A_DELAY_PS(307) G_DELAY_PS(0)	 
			0x850 A_DELAY_PS(0) G_DELAY_PS(0)	 
			0x854 A_DELAY_PS(0) G_DELAY_PS(0)	 
			0x870 A_DELAY_PS(785) G_DELAY_PS(0)	 
			0x874 A_DELAY_PS(0) G_DELAY_PS(0)	 
			0x878 A_DELAY_PS(0) G_DELAY_PS(0)	 
			0x87c A_DELAY_PS(613) G_DELAY_PS(0)	 
			0x880 A_DELAY_PS(0) G_DELAY_PS(0)	 
			0x884 A_DELAY_PS(0) G_DELAY_PS(0)	 
			0x888 A_DELAY_PS(683) G_DELAY_PS(0)	 
			0x88c A_DELAY_PS(0) G_DELAY_PS(0)	 
			0x890 A_DELAY_PS(0) G_DELAY_PS(0)	 
			0x894 A_DELAY_PS(835) G_DELAY_PS(0)	 
			0x898 A_DELAY_PS(0) G_DELAY_PS(0)	 
			0x89c A_DELAY_PS(0) G_DELAY_PS(0)	 
		>;
	};
	mmc4_iodelay_sdr12_hs_sdr25_rev11_conf: mmc4_iodelay_sdr12_hs_sdr25_rev11_conf {
		pinctrl-pin-array = <
			0x840 A_DELAY_PS(0) G_DELAY_PS(0)	 
			0x848 A_DELAY_PS(2651) G_DELAY_PS(0)	 
			0x84c A_DELAY_PS(1572) G_DELAY_PS(0)	 
			0x850 A_DELAY_PS(0) G_DELAY_PS(0)	 
			0x854 A_DELAY_PS(0) G_DELAY_PS(0)	 
			0x870 A_DELAY_PS(1913) G_DELAY_PS(0)	 
			0x874 A_DELAY_PS(0) G_DELAY_PS(0)	 
			0x878 A_DELAY_PS(0) G_DELAY_PS(0)	 
			0x87c A_DELAY_PS(1721) G_DELAY_PS(0)	 
			0x880 A_DELAY_PS(0) G_DELAY_PS(0)	 
			0x884 A_DELAY_PS(0) G_DELAY_PS(0)	 
			0x888 A_DELAY_PS(1891) G_DELAY_PS(0)	 
			0x88c A_DELAY_PS(0) G_DELAY_PS(0)	 
			0x890 A_DELAY_PS(0) G_DELAY_PS(0)	 
			0x894 A_DELAY_PS(1919) G_DELAY_PS(0)	 
			0x898 A_DELAY_PS(0) G_DELAY_PS(0)	 
			0x89c A_DELAY_PS(0) G_DELAY_PS(0)	 
		>;
	};
	mmc4_iodelay_sdr12_hs_sdr25_rev20_conf: mmc4_iodelay_sdr12_hs_sdr25_rev20_conf {
		pinctrl-pin-array = <
			0x840 A_DELAY_PS(0) G_DELAY_PS(0)	 
			0x848 A_DELAY_PS(1147) G_DELAY_PS(0)	 
			0x84c A_DELAY_PS(1834) G_DELAY_PS(0)	 
			0x850 A_DELAY_PS(0) G_DELAY_PS(0)	 
			0x854 A_DELAY_PS(0) G_DELAY_PS(0)	 
			0x870 A_DELAY_PS(2165) G_DELAY_PS(0)	 
			0x874 A_DELAY_PS(0) G_DELAY_PS(0)	 
			0x878 A_DELAY_PS(0) G_DELAY_PS(0)	 
			0x87c A_DELAY_PS(1929) G_DELAY_PS(64)	 
			0x880 A_DELAY_PS(0) G_DELAY_PS(0)	 
			0x884 A_DELAY_PS(0) G_DELAY_PS(0)	 
			0x888 A_DELAY_PS(1935) G_DELAY_PS(128)	 
			0x88c A_DELAY_PS(0) G_DELAY_PS(0)	 
			0x890 A_DELAY_PS(0) G_DELAY_PS(0)	 
			0x894 A_DELAY_PS(2172) G_DELAY_PS(44)	 
			0x898 A_DELAY_PS(0) G_DELAY_PS(0)	 
			0x89c A_DELAY_PS(0) G_DELAY_PS(0)	 
		>;
	};
};
